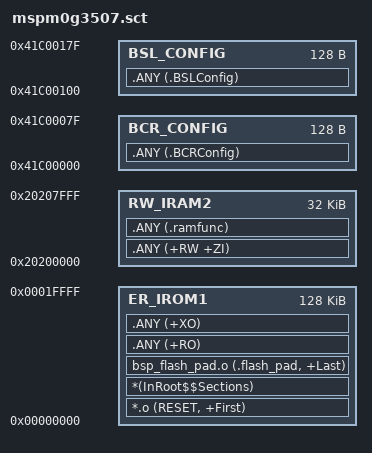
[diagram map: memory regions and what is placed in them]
; *************************************************************
; *** Scatter-Loading Description File generated by uVision ***
; *************************************************************

; *** Scatter 注释 ***
; ER_IROM1 末尾的 `bsp_flash_pad.o (.flash_pad, +Last)` 是 **MSPM0G3507 flash
; 64-bit 写**强约束的硬性补丁。dslite 烧录前会校验 PT_LOAD 段大小必须 8 字节
; 对齐（flash controller 一次写一个 64-bit 字），不对齐就抛
;   "Length of block is N, but it should be divisible by 8".
;
; ALIGNALL 8 只对齐 section START，不约束最后一个 section 的 END，所以还
; 需要一段固定 8 字节、自身 8-byte aligned 的占位 section 强制 `+Last`，
; 配合 `template/hardware/bsp_flash_pad.c` 里
; `__attribute__((section(".flash_pad"), aligned(8)))` 定义的
; `const uint64_t _flash_image_pad`。
;
; **selector 写法的两个独立约束**（缺一不可）：
;
;   1. 模块级 selector 优先级 > `.ANY` —— 这是 ARM 文档「Section selection
;      rules」里"most specific first"的硬保证。曾用 `.ANY3 (.flash_pad, +Last)`
;      + `.ANY1 (+RO)` 想靠 .ANYn 优先级抢，**实测仍被 `.ANY1 (+RO)` 拦下**：
;      12588 → 12604，仍 mod 8 = 4，未对齐。所以必须走模块级。
;
;   2. `+Last` 只能跟"单一 section"或"单一属性"selector —— 这是 ARMCLANG
;      armlink `L6234E: Last must follow a single selector` 的约束。曾写成
;      `bsp_flash_pad.o (+Last)`（等价"该 .o 所有 section"），被链接器
;      **直接拒**报 L6234E。所以必须再加 section 名 `.flash_pad` 收窄。
;
; 综上，唯一同时满足两条的写法是 `<obj>.o (<section_name>, +Last)`，模块
; + 节名双锁定，最特异性、单一 section。armlink 必接受。
;
; 同理上面 `*.o (RESET, +First)` 也是模块级（`*.o` 通配模块）+ section 名
; 双重选择，`.flash_pad` 名字不是 RESET，不会被它抢。
;
; 详见 docs/TaskLog/Stage1-IMU-BT-Telemetry.md §8.6。

LR_IROM1 0x00000000 0x00020000  {    ; load region size_region
  ER_IROM1 0x00000000 ALIGNALL 8 0x00020000  {  ; load address = execution address
   *.o (RESET, +First)
   *(InRoot$$Sections)
   bsp_flash_pad.o (.flash_pad, +Last)    ; 8-byte 尾填充：模块+节名双锁定 → 既高于 .ANY 又满足 +Last 单 section 约束
   .ANY (+RO)
   .ANY (+XO)
  }
  RW_IRAM2 0x20200000 0x00008000  {  ; RW data
   .ANY (+RW +ZI)
   .ANY (.ramfunc)
  }
}

LR_BCR 0x41C00000 0x00000100  {    ; load region size_region
  BCR_CONFIG 0x41C00000 0x00000080{
	.ANY (.BCRConfig)
  }
}

LR_BSL 0x41C00100 0x00000100  {    ; load region size_region
   BSL_CONFIG 0x41C00100 0x00000080{
	.ANY (.BSLConfig)
  }
}
